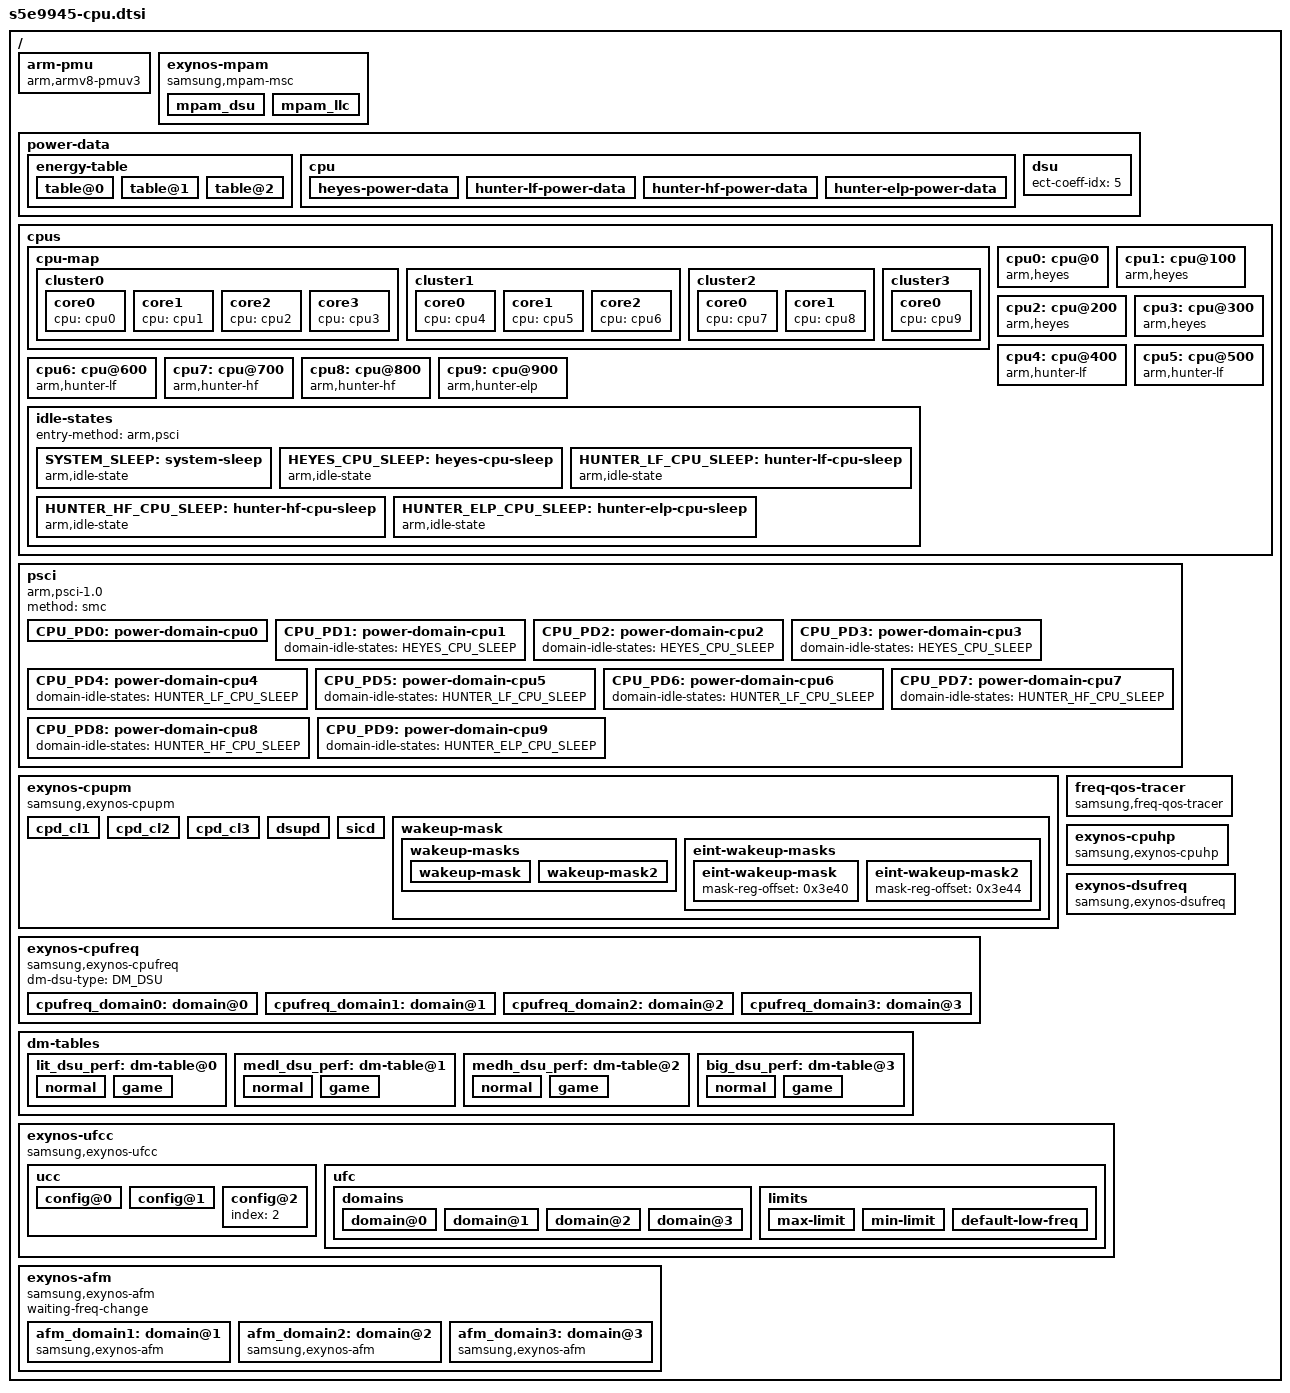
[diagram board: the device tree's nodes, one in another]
/*
 * SAMSUNG S5E9945 SoC CPU device tree source
 *
 * Copyright (c) 2022 Samsung Electronics Co., Ltd.
 *             http://www.samsung.com
 *
 * SAMSUNG EXYNOS9945 SoC device nodes are listed in this file.
 * EXYNOS based board files can include this file and provide
 * values for board specfic bindings.
 *
 * This program is free software; you can redistribute it and/or modify
 * it under the terms of the GNU General Public License version 2 as
 * published by the Free Software Foundation.
 */

#include <dt-bindings/soc/samsung/cpupm.h>

/ {
        arm-pmu {
                compatible = "arm,armv8-pmuv3";
                interrupts = <GIC_PPI 7 (GIC_CPU_MASK_SIMPLE(8) | IRQ_TYPE_LEVEL_HIGH)>;
        };

	exynos-mpam {
		#define MSC_DSU 0
		#define MSC_LLC 1

		compatible = "samsung,mpam-msc";

		mpam_dsu {
			msc-type = <MSC_DSU>;
			base = <0x1d010000>;
			size = <0x10000>;
		};
		mpam_llc {
			msc-type = <MSC_LLC>;
			base = <0x22800000>;
			size = <0x10000>;
			cpbm-nbits = <16>;
			llc-request-count = <8>;
		};
	};

	power-data {
		#define CPU_CL0		"0-3"
		#define CPU_CL1L	"4-6"
		#define CPU_CL1H	"7-8"
		#define CPU_CL2		"9"
		#define CPU_ALL		"0-9"

		#define CPUCL0_DMIPS_PER_MHZ	781
		#define CPUCL1L_DMIPS_PER_MHZ	1378
		#define CPUCL1H_DMIPS_PER_MHZ	1378
		#define CPUCL2_DMIPS_PER_MHZ	1631

		#define CPUCL0_DP_COEFF		170
		#define CPUCL1L_DP_COEFF	444
		#define CPUCL1H_DP_COEFF	499
		#define CPUCL2_DP_COEFF		991

		energy-table {
			table@0 {
				mips = <494 640 640 690>;
				dynamic-coeff = <258 389 406 981>;
				dynamic-intercept = <(-34) 18 28 48>;
			};
			table@1 {
				default_table;
				mips = <695 1352 1335 1713>;
				dynamic-coeff = <201 468 532 1310>;
				dynamic-intercept = <(-15) 8 12 20>;
			};
			table@2 {
				mips = <2499 6545 6545 7826>;
				dynamic-coeff = <160 519 571 1145>;
			};
		};

		cpu {
			heyes-power-data {
				/* default power data */
				cpus = CPU_CL0;
				capacity-dmips-mhz = <CPUCL0_DMIPS_PER_MHZ>;
				dynamic-power-coefficient = <CPUCL0_DP_COEFF>;
				tz-name = "LITTLE";

				/* dynamic power w/ ECT */
				ect-coeff-idx = <3>;
			};

			hunter-lf-power-data {
				/* default power data */
				cpus = CPU_CL1L;
				capacity-dmips-mhz = <CPUCL1L_DMIPS_PER_MHZ>;
				dynamic-power-coefficient = <CPUCL1L_DP_COEFF>;
				tz-name = "MIDL";

				/* dynamic power w/ ECT */
				ect-coeff-idx = <2>;
			};

			hunter-hf-power-data {
				/* default power data */
				cpus = CPU_CL1H;
				capacity-dmips-mhz = <CPUCL1H_DMIPS_PER_MHZ>;
				dynamic-power-coefficient = <CPUCL1H_DP_COEFF>;
				tz-name = "MIDH";

				/* dynamic power w/ ECT */
				ect-coeff-idx = <1>;
			};

			hunter-elp-power-data {
				/* default power data */
				cpus = CPU_CL2;
				capacity-dmips-mhz = <CPUCL2_DMIPS_PER_MHZ>;
				dynamic-power-coefficient = <CPUCL2_DP_COEFF>;
				tz-name = "BIG";

				/* dynamic power w/ ECT */
				ect-coeff-idx = <0>;
			};
		};

		dsu {
			/* dynamic power w/ ECT */
			ect-coeff-idx = <5>;
		};
	};
	cpus {
		#address-cells = <2>;
		#size-cells = <0>;

		cpu-map {
			cluster0 {
				core0 {
					cpu = <&cpu0>;
				};
				core1 {
					cpu = <&cpu1>;
				};
				core2 {
					cpu = <&cpu2>;
				};
				core3 {
					cpu = <&cpu3>;
				};
			};
			cluster1 {
				core0 {
					cpu = <&cpu4>;
				};
				core1 {
					cpu = <&cpu5>;
				};
				core2 {
					cpu = <&cpu6>;
				};
			};
			cluster2 {
				core0 {
					cpu = <&cpu7>;
				};
				core1 {
					cpu = <&cpu8>;
				};
			};
			cluster3 {
				core0 {
					cpu = <&cpu9>;
				};
			};
		};

		cpu0: cpu@0 {
			device_type = "cpu";
			compatible = "arm,heyes", "arm,armv9";
			reg = <0x0 0x0000>;
			capacity-dmips-mhz = <CPUCL0_DMIPS_PER_MHZ>;
			dynamic-power-coefficient = <CPUCL0_DP_COEFF>;
			enable-method = "psci";
			power-domains = <&CPU_PD0>;
			power-domain-names = "psci";
		};
		cpu1: cpu@100 {
			device_type = "cpu";
			compatible = "arm,heyes", "arm,armv9";
			reg = <0x0 0x0100>;
			capacity-dmips-mhz = <CPUCL0_DMIPS_PER_MHZ>;
			dynamic-power-coefficient = <CPUCL0_DP_COEFF>;
			enable-method = "psci";
			power-domains = <&CPU_PD1>;
			power-domain-names = "psci";
		};
		cpu2: cpu@200 {
			device_type = "cpu";
			compatible = "arm,heyes", "arm,armv9";
			reg = <0x0 0x0200>;
			capacity-dmips-mhz = <CPUCL0_DMIPS_PER_MHZ>;
			dynamic-power-coefficient = <CPUCL0_DP_COEFF>;
			enable-method = "psci";
			power-domains = <&CPU_PD2>;
			power-domain-names = "psci";
		};
		cpu3: cpu@300 {
			device_type = "cpu";
			compatible = "arm,heyes", "arm,armv9";
			reg = <0x0 0x0300>;
			capacity-dmips-mhz = <CPUCL0_DMIPS_PER_MHZ>;
			dynamic-power-coefficient = <CPUCL0_DP_COEFF>;
			enable-method = "psci";
			power-domains = <&CPU_PD3>;
			power-domain-names = "psci";
		};
		cpu4: cpu@400 {
			device_type = "cpu";
			compatible = "arm,hunter-lf", "arm,armv9";
			reg = <0x0 0x0400>;
			capacity-dmips-mhz = <CPUCL1L_DMIPS_PER_MHZ>;
			dynamic-power-coefficient = <CPUCL1L_DP_COEFF>;
			enable-method = "psci";
			power-domains = <&CPU_PD4>;
			power-domain-names = "psci";
		};
		cpu5: cpu@500 {
			device_type = "cpu";
			compatible = "arm,hunter-lf", "arm,armv9";
			reg = <0x0 0x0500>;
			capacity-dmips-mhz = <CPUCL1L_DMIPS_PER_MHZ>;
			dynamic-power-coefficient = <CPUCL1L_DP_COEFF>;
			enable-method = "psci";
			power-domains = <&CPU_PD5>;
			power-domain-names = "psci";
		};
		cpu6: cpu@600 {
			device_type = "cpu";
			compatible = "arm,hunter-lf", "arm,armv9";
			reg = <0x0 0x0600>;
			capacity-dmips-mhz = <CPUCL1L_DMIPS_PER_MHZ>;
			dynamic-power-coefficient = <CPUCL1L_DP_COEFF>;
			enable-method = "psci";
			power-domains = <&CPU_PD6>;
			power-domain-names = "psci";
		};
		cpu7: cpu@700 {
			device_type = "cpu";
			compatible = "arm,hunter-hf", "arm,armv9";
			reg = <0x0 0x0700>;
			capacity-dmips-mhz = <CPUCL1H_DMIPS_PER_MHZ>;
			dynamic-power-coefficient = <CPUCL1H_DP_COEFF>;
			enable-method = "psci";
			power-domains = <&CPU_PD7>;
			power-domain-names = "psci";
		};
		cpu8: cpu@800 {
			device_type = "cpu";
			compatible = "arm,hunter-hf", "arm,armv9";
			reg = <0x0 0x0800>;
			capacity-dmips-mhz = <CPUCL1H_DMIPS_PER_MHZ>;
			dynamic-power-coefficient = <CPUCL1H_DP_COEFF>;
			enable-method = "psci";
			power-domains = <&CPU_PD8>;
			power-domain-names = "psci";
		};
		cpu9: cpu@900 {
			device_type = "cpu";
			compatible = "arm,hunter-elp", "arm,armv9";
			reg = <0x0 0x0900>;
			capacity-dmips-mhz = <CPUCL2_DMIPS_PER_MHZ>;
			dynamic-power-coefficient = <CPUCL2_DP_COEFF>;
			enable-method = "psci";
			power-domains = <&CPU_PD9>;
			power-domain-names = "psci";
		};

		idle-states {
			entry-method = "arm,psci";

			SYSTEM_SLEEP: system-sleep {
				idle-state-name = "sleep";
				compatible = "arm,idle-state";
				arm,psci-suspend-param = <0x3010000>;
				entry-latency-us = <2147483647>;
				exit-latency-us = <2147483647>;
				min-residency-us = <4294967295>;
				status = "okay";
			};

			HEYES_CPU_SLEEP: heyes-cpu-sleep {
				idle-state-name = "c2";
				compatible = "arm,idle-state";
				arm,psci-suspend-param = <0x0010000>;
				entry-latency-us = <70>;
				exit-latency-us = <160>;
				min-residency-us = <2000>;
				status = "okay";
			};

			HUNTER_LF_CPU_SLEEP: hunter-lf-cpu-sleep {
				idle-state-name = "c2";
				compatible = "arm,idle-state";
				arm,psci-suspend-param = <0x0010000>;
				entry-latency-us = <150>;
				exit-latency-us = <190>;
				min-residency-us = <2500>;
				status = "okay";
			};

			HUNTER_HF_CPU_SLEEP: hunter-hf-cpu-sleep {
				idle-state-name = "c2";
				compatible = "arm,idle-state";
				arm,psci-suspend-param = <0x0010000>;
				entry-latency-us = <150>;
				exit-latency-us = <190>;
				min-residency-us = <2500>;
				status = "okay";
			};

			HUNTER_ELP_CPU_SLEEP: hunter-elp-cpu-sleep {
				idle-state-name = "c2";
				compatible = "arm,idle-state";
				arm,psci-suspend-param = <0x0010000>;
				entry-latency-us = <235>;
				exit-latency-us = <220>;
				min-residency-us = <3500>;
				status = "okay";
			};
		};
	};

	psci {
		compatible = "arm,psci-1.0";
		method = "smc";

		CPU_PD0: power-domain-cpu0 {
		#power-domain-cells = <0>;
		domain-idle-states = <&HEYES_CPU_SLEEP>, <&SYSTEM_SLEEP>;
		};
		CPU_PD1: power-domain-cpu1 {
		#power-domain-cells = <0>;
		domain-idle-states = <&HEYES_CPU_SLEEP>;
		};
		CPU_PD2: power-domain-cpu2 {
		#power-domain-cells = <0>;
		domain-idle-states = <&HEYES_CPU_SLEEP>;
		};
		CPU_PD3: power-domain-cpu3 {
		#power-domain-cells = <0>;
		domain-idle-states = <&HEYES_CPU_SLEEP>;
		};
		CPU_PD4: power-domain-cpu4 {
		#power-domain-cells = <0>;
		domain-idle-states = <&HUNTER_LF_CPU_SLEEP>;
		};
		CPU_PD5: power-domain-cpu5 {
		#power-domain-cells = <0>;
		domain-idle-states = <&HUNTER_LF_CPU_SLEEP>;
		};
		CPU_PD6: power-domain-cpu6 {
		#power-domain-cells = <0>;
		domain-idle-states = <&HUNTER_LF_CPU_SLEEP>;
		};
		CPU_PD7: power-domain-cpu7 {
		#power-domain-cells = <0>;
		domain-idle-states = <&HUNTER_HF_CPU_SLEEP>;
		};
		CPU_PD8: power-domain-cpu8 {
		#power-domain-cells = <0>;
		domain-idle-states = <&HUNTER_HF_CPU_SLEEP>;
		};
		CPU_PD9: power-domain-cpu9 {
		#power-domain-cells = <0>;
		domain-idle-states = <&HUNTER_ELP_CPU_SLEEP>;
		};
	};

	exynos-cpupm {
		compatible = "samsung,exynos-cpupm";
		status = "okay";

		cpd_cl1 {
			device_type = "cpupm";
			target-residency = <10000>;
			type = <POWERMODE_TYPE_CLUSTER>;
			cal-id = <1>;
			siblings = CPU_CL1L;
			entry-allowed = CPU_CL1L;
		};

		cpd_cl2 {
			device_type = "cpupm";
			target-residency = <10000>;
			type = <POWERMODE_TYPE_CLUSTER>;
			cal-id = <2>;
			siblings = CPU_CL1H;
			entry-allowed = CPU_CL1H;
		};

		cpd_cl3 {
			device_type = "cpupm";
			target-residency = <10000>;
			type = <POWERMODE_TYPE_CLUSTER>;
			cal-id = <3>;
			siblings = CPU_CL2;
			entry-allowed = CPU_CL2;
		};

		dsupd {
			device_type = "cpupm";
			target-residency = <10000>;
			type = <POWERMODE_TYPE_DSU>;
			siblings = CPU_ALL;
			entry-allowed = CPU_ALL;
		};

		sicd {
			device_type = "cpupm";
			target-residency = <10000>;
			type = <POWERMODE_TYPE_SYSTEM>;
			siblings = CPU_ALL;
			entry-allowed = CPU_ALL;
			deferred-enabled;
		};

		wakeup-mask {
			wakeup-masks {
				wakeup-mask {
					mask-reg-offset = <0x3b44>;
					stat-reg-offset = <0x3b50>;
					mask = <0xffc00000>;
				};
				wakeup-mask2 {
					mask-reg-offset = <0x3b64>;
					stat-reg-offset = <0x3b54>;
					mask = <0x00>;
				};
			};

			eint-wakeup-masks {
				eint-wakeup-mask {
					mask-reg-offset = <0x3e40>;
				};
				eint-wakeup-mask2 {
					mask-reg-offset = <0x3e44>;
				};
			};
		};
	};

	exynos-cpufreq {
		compatible = "samsung,exynos-cpufreq";
		status = "okay";
		dm-dsu-type = <DM_DSU>;

		cpufreq_domain0: domain@0 {
			sibling-cpus = CPU_CL0;
			cal-id = <ACPM_DVFS_CPUCL0>;
			dm-type = <DM_CPUCL0>;
			dss-type = <ESS_FLAG_CPU_CL0>;

			min-freq = <400000>;

			fast-switch;
			thread-run-on = "0-3";

			pm_qos-booting = <1440000>;

			#cooling-cells = <2>; /* min followed by max */
			ect-coeff-index = <3>;
			tz-cooling-name = "LITTLE";

			freq-table = <  400000
					576000
					672000
					768000
					864000
					960000
					1056000
					1152000
					1248000
					1344000
					1440000
					1536000
					1632000
					1728000
					1824000
					1920000
					1959000
					2016000
					2112000 >;
		};

		cpufreq_domain1: domain@1 {
			sibling-cpus = CPU_CL1L;
			cal-id = <ACPM_DVFS_CPUCL1L>;
			dm-type = <DM_CPUCL1L>;
			dss-type = <ESS_FLAG_CPU_CL1L>;

			min-freq = <672000>;

			fast-switch;
			thread-run-on = "0-3";

			pm_qos-booting = <1920000>;

			#cooling-cells = <2>; /* min followed by max */
			ect-coeff-index = <2>;
			tz-cooling-name = "MIDL";

			freq-table = <  576000
					672000
					768000
					864000
					960000
					1056000
					1152000
					1248000
					1344000
					1440000
					1536000
					1632000
					1728000
					1824000
					1920000
					2016000
					2112000
					2208000
					2304000
					2400000
					2496000
					2592000 >;
		};

		cpufreq_domain2: domain@2 {
			sibling-cpus = CPU_CL1H;
			cal-id = <ACPM_DVFS_CPUCL1H>;
			dm-type = <DM_CPUCL1H>;
			dss-type = <ESS_FLAG_CPU_CL1H>;

			min-freq = <672000>;

			fast-switch;
			thread-run-on = "0-3";

			pm_qos-booting = <2304000>;

			#cooling-cells = <2>; /* min followed by max */
			ect-coeff-index = <1>;
			tz-cooling-name = "MIDH";

			freq-table = <  576000
					672000
					768000
					864000
					960000
					1056000
					1152000
					1248000
					1344000
					1440000
					1536000
					1632000
					1728000
					1824000
					1920000
					2016000
					2112000
					2208000
					2304000
					2400000
					2496000
					2592000
					2688000
					2784000
					2880000
					2900000 >;
		};

		cpufreq_domain3: domain@3 {
			sibling-cpus = CPU_CL2;
			cal-id = <ACPM_DVFS_CPUCL2>;
			dm-type = <DM_CPUCL2>;
			dss-type = <ESS_FLAG_CPU_CL2>;

			min-freq = <672000>;

			fast-switch;
			thread-run-on = "0-3";

			pm_qos-booting = <2112000>;

			#cooling-cells = <2>; /* min followed by max */
			ect-coeff-index = <0>;
			tz-cooling-name = "BIG";

			freq-table = <  576000
					672000
					768000
					864000
					960000
					1056000
					1152000
					1248000
					1344000
					1440000
					1536000
					1632000
					1728000
					1824000
					1920000
					2016000
					2112000
					2208000
					2304000
					2400000
					2496000
					2592000
					2688000
					2784000
					2880000
					2976000
					3072000
					3168000
					3226000 >;
		};
	};

	freq-qos-tracer {
		compatible = "samsung,freq-qos-tracer";
		status = "okay";
	};

	dm-tables {
		lit_dsu_perf: dm-table@0 {
			const-type = <CONSTRAINT_MIN>;
			dm-slave = <DM_DSU>;
			master-cal-id = <ACPM_DVFS_CPUCL0>;
			slave-cal-id = <ACPM_DVFS_DSU>;

			normal {	 /* CPU	  DSU */
				table = <  400000  240000
					   576000  384000
					   672000  432000
					   768000  528000
					   864000  576000
					   960000  624000
					  1056000  720000
					  1152000  768000
					  1248000  816000
					  1344000  912000
					  1440000  960000
					  1536000 1008000
					  1632000 1104000
					  1728000 1152000
					  1824000 1200000
					  1920000 1248000
					  1959000 1296000
					  2016000 1344000
					  2112000 1392000 >;
			};

			game {		 /* CPU	  DSU */
				table = <  400000  200000
					   576000  288000
					   672000  336000
					   768000  384000
					   864000  432000
					   960000  480000
					  1056000  528000
					  1152000  576000
					  1248000  624000
					  1344000  672000
					  1440000  720000
					  1536000  768000
					  1632000 1104000
					  1728000 1152000
					  1824000 1200000
					  1920000 1248000
					  1959000 1296000
					  2016000 1344000
					  2112000 1392000 >;
			};
		};

		medl_dsu_perf: dm-table@1 {
			const-type = <CONSTRAINT_MIN>;
			dm-slave = <DM_DSU>;
			master-cal-id = <ACPM_DVFS_CPUCL1L>;
			slave-cal-id = <ACPM_DVFS_DSU>;
			multi-table;

			normal {	 /* CPU	  DSU */
				table = <  576000  267000
					   672000  267000
					   768000  528000
					   864000  576000
					   960000  624000
					  1056000  720000
					  1152000  768000
					  1248000  816000
					  1344000  864000
					  1440000  960000
					  1536000 1008000
					  1632000 1104000
					  1728000 1152000
					  1824000 1200000
					  1920000 1248000
					  2016000 1344000
					  2112000 1392000
					  2208000 1440000
					  2304000 1536000
					  2400000 1584000
					  2496000 1632000
					  2592000 1728000 >;
			};

			game {		 /* CPU	  DSU */
				table = <  576000  288000
					   672000  336000
					   768000  384000
					   864000  432000
					   960000  480000
					  1056000  528000
					  1152000  576000
					  1248000  624000
					  1344000  672000
					  1440000  720000
					  1536000  768000
					  1632000  816000
					  1728000  864000
					  1824000 1200000
					  1920000 1248000
					  2016000 1344000
					  2112000 1392000
					  2208000 1440000
					  2304000 1536000
					  2400000 1584000
					  2496000 1632000
					  2592000 1728000 >;
			};
		};

		medh_dsu_perf: dm-table@2 {
			const-type = <CONSTRAINT_MIN>;
			dm-slave = <DM_DSU>;
			master-cal-id = <ACPM_DVFS_CPUCL1H>;
			slave-cal-id = <ACPM_DVFS_DSU>;

			normal {	 /* CPU	  DSU */
				table = <  576000  267000
					   672000  267000
					   768000  528000
					   864000  576000
					   960000  624000
					  1056000  720000
					  1152000  768000
					  1248000  816000
					  1344000  912000
					  1440000  960000
					  1536000 1008000
					  1632000 1104000
					  1728000 1152000
					  1824000 1200000
					  1920000 1248000
					  2016000 1344000
					  2112000 1392000
					  2208000 1440000
					  2304000 1536000
					  2400000 1584000
					  2496000 1728000
					  2592000 1805000
					  2688000 1805000
					  2784000 1920000
					  2880000 2016000
					  2900000 2016000 >;
			};

			game {		 /* CPU	  DSU */
				table = <  576000  288000
					   672000  336000
					   768000  384000
					   864000  432000
					   960000  480000
					  1056000  528000
					  1152000  576000
					  1248000  624000
					  1344000  672000
					  1440000  720000
					  1536000  768000
					  1632000  816000
					  1728000  864000
					  1824000 1200000
					  1920000 1248000
					  2016000 1344000
					  2112000 1392000
					  2208000 1440000
					  2304000 1536000
					  2400000 1584000
					  2496000 1632000
					  2592000 1632000
					  2688000 1632000
					  2784000 1632000
					  2880000 1632000
					  2900000 1632000 >;
			};
		};

		big_dsu_perf: dm-table@3 {
			const-type = <CONSTRAINT_MIN>;
			dm-slave = <DM_DSU>;
			master-cal-id = <ACPM_DVFS_CPUCL2>;
			slave-cal-id = <ACPM_DVFS_DSU>;

			normal {	 /* CPU	  DSU */
				table = <  576000  267000
					   672000  267000
					   768000  528000
					   864000  576000
					   960000  624000
					  1056000  720000
					  1152000  768000
					  1248000  816000
					  1344000  912000
					  1440000  960000
					  1536000 1008000
					  1632000 1104000
					  1728000 1152000
					  1824000 1200000
					  1920000 1248000
					  2016000 1344000
					  2112000 1392000
					  2208000 1440000
					  2304000 1536000
					  2400000 1584000
					  2496000 1728000
					  2592000 1805000
					  2688000 1805000
					  2784000 1920000
					  2880000 2016000
					  2976000 2016000
					  3072000 2016000
					  3168000 2016000
					  3226000 2016000 >;
			};

			game {		 /* CPU	  DSU */
				table = <  576000  288000
					   672000  336000
					   768000  384000
					   864000  432000
					   960000  480000
					  1056000  528000
					  1152000  576000
					  1248000  624000
					  1344000  672000
					  1440000  720000
					  1536000  768000
					  1632000  816000
					  1728000  864000
					  1824000 1200000
					  1920000 1248000
					  2016000 1344000
					  2112000 1392000
					  2208000 1440000
					  2304000 1536000
					  2400000 1584000
					  2496000 1632000
					  2592000 1632000
					  2688000 1632000
					  2784000 1632000
					  2880000 1632000
					  2976000 1632000
					  3072000 1632000
					  3168000 1632000
					  3226000 1632000 >;
			};
		};
	};

	exynos-cpuhp {
		compatible = "samsung,exynos-cpuhp";
		status = "okay";
	};

	exynos-dsufreq {
		compatible = "samsung,exynos-dsufreq";
		status = "okay";

		cal-id = <ACPM_DVFS_DSU>;
		dm-type = <DM_DSU>;
		dss-type = <ESS_FLAG_DSU>;

		freq-table = <	288000
				384000
				480000
				576000
				672000
				768000
				864000
				960000
				1056000
				1152000
				1248000
				1344000
				1440000
				1536000
				1632000
				1728000
				1824000
				1920000
				2016000	>;
	};

	exynos-ufcc {
		compatible = "samsung,exynos-ufcc";
		status = "okay";

		ucc {
			config@0 {
				index = <0>;
				allowed = "4-9";
			};
			config@1 {
				index = <1>;
				allowed = "9";
			};
			config@2 {
				index = <2>;
			};
		};

		ufc {
			table-info = "vfreq",
				"big",
				"mid_h",
				"mid_l",
				"lit",
				"emstune",
				"strict";

			domains {
				domain@0 {
					domain-name = "lit";
					shared-cpus = CPU_CL0;
				};
				domain@1 {
					domain-name = "mid_l";
					shared-cpus = CPU_CL1L;
					allow-disable-cpus;
				};
				domain@2 {
					domain-name = "mid_h";
					shared-cpus = CPU_CL1H;
					allow-disable-cpus;
				};
				domain@3 {
					domain-name = "big";
					shared-cpus = CPU_CL2;
					allow-disable-cpus;
				};
			};

			limits {
				/* lowest frequency at or above target */
				#define MIN_LIMIT		0
				/* highest frequency below or at target */
				#define MAX_LIMIT		1

				max-limit {
					relation = <MAX_LIMIT>;
					table = <
						3226000	3226000	2900000	2592000	1959000	0	0
						3168000	3168000	2784000	2304000	1824000	0	0
						3072000	3072000	2784000	2304000	1824000	0	0
						2976000	2976000	2784000	2304000	1824000	0	0
						2880000	2880000	2784000	2304000	1824000	0	0
						2784000	2784000	2784000	2304000	1824000	0	0
						2688000	2688000	2688000	2304000	1824000	0	0
						2592000	2592000	2592000	2304000	1728000	0	0
						2496000	2496000	2496000	2304000	1728000	0	0
						2400000	2400000	2400000	2304000	1728000	0	0
						2304000	2304000	2304000	2304000	1728000	0	0
						2208000	2208000	2208000	2208000	1728000	0	0
						2112000	2112000	2112000	2112000	1728000	0	0
						2016000	2016000	2016000	2016000	1632000	0	0
						1920000	1920000	1920000	1920000	1632000	0	0
						1900000	1920000	1824000	1824000	1632000	0	0
						1824000	1824000	1824000	1824000	1632000	0	0
						1800000	1824000	1728000	1728000	1632000	0	0
						1728000	1728000	1728000	1728000	1632000	0	0
						1700000	1728000	1632000	1632000	1632000	0	0
						1632000	1632000	1632000	1632000	1536000	0	0
						1600000	1632000	1536000	1536000	1536000	0	0
						1536000	1536000	1536000	1536000	1536000	0	0
						1500000	1536000	1440000	1440000	1536000	0	0
						1440000	1440000	1440000	1440000	1440000	0	0
						1344000	1344000	1344000	1344000	1440000	0	0
						1248000	1248000	1248000	1248000	1344000	0	0
						1152000	1152000	1152000	1152000	1344000	0	0
						1056000	1056000	1056000	1056000	1248000	0	0
						960000	960000	960000	960000	1152000	0	0
						864000	864000	864000	864000	1152000	0	0
						768000	768000	768000	768000	1152000	0	0
						672000	672000	672000	672000	1152000	0	0
						576000	576000	576000	576000	1152000	0	0
						>;
				};
				min-limit {
					relation = <MIN_LIMIT>;
					table = <
						3226000	3226000	2784000	2304000	1824000	2	1
						3168000	3168000	2784000	2304000	1824000	2	1
						3072000	3072000	2784000	2304000	1824000	2	1
						2976000	2976000	2784000	2304000	1824000	2	1
						2880000	2880000	2784000	2304000	1824000	2	1
						2784000	2784000	2784000	2304000	1824000	2	1
						2688000	2688000	2688000	2304000	1824000	2	1
						2592000	2592000	2592000	2304000	1824000	2	1
						2496000	2496000	2496000	2304000	1824000	2	1
						2400000	2400000	2400000	2304000	1728000	2	1
						2304000	2304000	2304000	2304000	1728000	2	1
						2208000	2208000	2208000	2208000	1728000	2	1
						2112000	2112000	2112000	2112000	1728000	2	1
						2016000	2016000	2016000	2016000	1728000	2	1
						1920000	1920000	1920000	1920000	1728000	2	1
						1900000	1920000	1824000	1824000	1728000	2	1
						1824000	1824000	1824000	1824000	960000	1	1
						1800000	1824000	1728000	1728000	960000	1	1
						1728000	1728000	1728000	1728000	960000	1	1
						1700000	1728000	1632000	1632000	960000	1	1
						1632000	1632000	1632000	1632000	960000	1	1
						1600000	1632000	1536000	1536000	960000	1	1
						1536000	1536000	1536000	1536000	960000	1	1
						1500000	1536000	1440000	1440000	960000	1	1
						1440000	1440000	1440000	1440000	960000	1	1
						1344000	1344000	1344000	1344000	960000	1	1
						1248000	1248000	1248000	1248000	960000	1	1
						1152000	1152000	1152000	1152000	768000	1	1
						1056000	1056000	1056000	1056000	768000	1	1
						960000	960000	960000	960000	768000	1	0
						864000	864000	864000	864000	768000	1	0
						768000	768000	768000	768000	768000	0	0
						672000	672000	672000	672000	768000	0	0
						576000	576000	576000	576000	768000	0	0
						>;
				};
				default-low-freq {
					relation = <MIN_LIMIT>;
					table = <
						3226000	0	2112000	1920000	1536000	0	0
						3168000	0	2112000	1920000	1536000	0	0
						3072000	0	2112000	1920000	1536000	0	0
						2976000	0	2112000	1920000	1536000	0	0
						2880000	0	2112000	1920000	1536000	0	0
						2784000	0	2112000	1920000	1536000	0	0
						2688000	0	2112000	1920000	1536000	0	0
						2592000	0	2112000	1920000	960000	0	0
						2496000	0	2112000	1920000	960000	0	0
						2400000	0	2112000	1920000	960000	0	0
						2304000	0	2112000	1920000	960000	0	0
						2208000	0	2112000	1920000	960000	0	0
						2112000	0	1152000	1920000	960000	0	0
						2016000	0	1152000	1920000	960000	0	0
						1920000	0	1152000	1152000	960000	0	0
						1900000	0	1152000	1152000	960000	0	0
						1824000	0	1152000	1152000	768000	0	0
						1800000	0	1152000	1152000	768000	0	0
						1728000	0	1152000	1152000	768000	0	0
						1700000	0	1152000	1152000	768000	0	0
						1632000	0	1152000	1152000	768000	0	0
						1600000	0	1152000	1152000	768000	0	0
						1536000	0	1152000	1152000	768000	0	0
						1500000	0	1152000	1152000	768000	0	0
						1440000	0	1152000	1152000	768000	0	0
						1344000	0	1152000	1152000	768000	0	0
						1248000	0	1152000	1152000	768000	0	0
						1152000	0	0	0	0	0	0
						1056000	0	0	0	0	0	0
						960000	0	0	0	0	0	0
						864000	0	0	0	0	0	0
						768000	0	0	0	0	0	0
						672000	0	0	0	0	0	0
						576000	0	0	0	0	0	0
						>;
				};
			};
		};
	};

	exynos-afm {
		#define MAIN_PMIC	1
		#define SUB_PMIC	2
		#define SUB2_PMIC	3

		compatible = "samsung,exynos-afm";
		status = "okay";
		waiting-freq-change;

		afm_domain1: domain@1 {
			device_type = "afm-domain";
			compatible = "samsung,exynos-afm";
			interrupts = <GIC_SPI INTREQ__OCP_REATOR_CPUCL0_1L IRQ_TYPE_LEVEL_HIGH>;
			sibling-cpus = CPU_CL1L;
			interrupt-src = <SUB_PMIC>;
			s2mps-afm-offset = <0x24>;
			htu-base-addr = <0x1DC90000>;
			down-step = <1>;
			max-freq-wo-afm = <2002000>;
			release-duration = <15>;
		};
		afm_domain2: domain@2 {
			device_type = "afm-domain";
			compatible = "samsung,exynos-afm";
			interrupts = <GIC_SPI INTREQ__OCP_REATOR_CPUCL0_1H IRQ_TYPE_LEVEL_HIGH>;
			sibling-cpus = CPU_CL1H;
			interrupt-src = <SUB_PMIC>;
			s2mps-afm-offset = <0x2C>;
			htu-base-addr = <0x1DD60000>;
			down-step = <1>;
			max-freq-wo-afm = <2002000>;
			release-duration = <15>;
		};
		afm_domain3: domain@3 {
			device_type = "afm-domain";
			compatible = "samsung,exynos-afm";
			interrupts = <GIC_SPI INTREQ__OCP_REATOR_CPUCL0_2 IRQ_TYPE_LEVEL_HIGH>;
			sibling-cpus = CPU_CL2;
			interrupt-src = <SUB2_PMIC>;
			s2mps-afm-offset = <0x2C>;
			htu-base-addr = <0x1DCA0000>;
			down-step = <1>;
			max-freq-wo-afm = <2002000>;
			release-duration = <15>;
		};
	};
};
